# STM32H5E4xx register map
File version: 1.0
Registers are 32-bit, read-write, reset 0x0 unless marked. A register's access mark holds for its fields unless they carry their own. Offsets are from the block's base; [hi:lo] are bit positions; 'fields as' and 'values as' point back to an identical list.

## RSSLIB_PFUNC — RSSLib function pointer structure
Base 0x0BFB6068
0x00 DataProvisioning ro
0x10 JumpHDPLvl2 ro
0x14 JumpHDPLvl3 ro
0x18 JumpHDPLvl3NS ro

## NSSLIB_PFUNC — RSSLib secure callable function pointer structure
Base 0x0BFB606C
0x00 JumpHDPLvl2 ro
0x04 JumpHDPLvl3 ro

## WWDG
Base 0x40002C00
Same registers: WWDG_S 0x50002C00
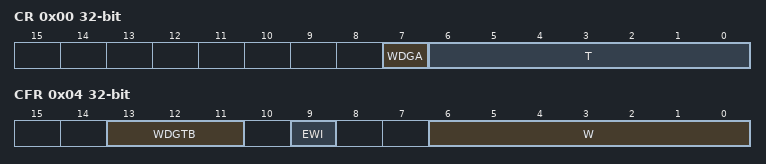
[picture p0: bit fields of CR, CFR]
0x00 CR — WWDG Control register
  [7] WDGA — Activation bit
  [6:0] T — T[6:0] bits (7-Bit counter (MSB to LSB))
0x04 CFR — WWDG Configuration register
  [13:11] WDGTB — WDGTB[2:0] bits (Timer Base)
    0=PRESCALER_1 (WWDG counter clock = (PCLK1/4096)/1); 1=PRESCALER_2 (WWDG counter clock = (PCLK1/4096)/2); 2=PRESCALER_4 (WWDG counter clock = (PCLK1/4096)/4); 3=PRESCALER_8 (WWDG counter clock = (PCLK1/4096)/8); 4=PRESCALER_16 (WWDG counter clock = (PCLK1/4096)/16); 5=PRESCALER_32 (WWDG counter clock = (PCLK1/4096)/32); 6=PRESCALER_64 (WWDG counter clock = (PCLK1/4096)/64); 7=PRESCALER_128 (WWDG counter clock = (PCLK1/4096)/128)
  [9] EWI — Early Wakeup Interrupt
  [6:0] W — W[6:0] bits (7-bit window value)
0x08 SR — WWDG Status register
  [0] EWIF — Early Wakeup Interrupt Flag

## IWDG
Base 0x40003000
Same registers: IWDG_S 0x50003000
0x00 KR — IWDG Key register
  [15:0] KEY — Key value (write only, read 0000h)
0x04 PR — IWDG Prescaler register
  [3:0] PR — PR[3:0] (Prescaler divider)
0x08 RLR — IWDG Reload register
  [11:0] RL — Watchdog counter reload value
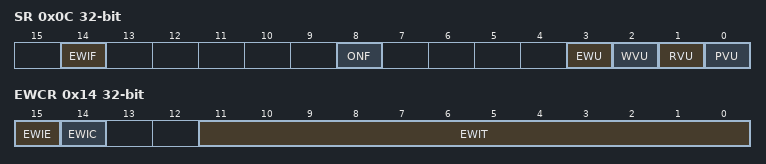
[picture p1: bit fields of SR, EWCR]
0x0C SR — IWDG Status register
  [14] EWIF — Watchdog early interrupt flag
  [8] ONF — Watchdog Enable status bit
  [3] EWU — Watchdog interrupt comparator value update
  [2] WVU — Watchdog counter window value update
  [1] RVU — Watchdog counter reload value update
  [0] PVU — Watchdog prescaler value update
0x10 WINR — IWDG Window register
  [11:0] WIN — Watchdog counter window value
0x14 EWCR — IWDG Early Wakeup register
  [15] EWIE — Watchdog early wakeup comparator value
  [14] EWIC — Watchdog early wakeup comparator value
  [11:0] EWIT — Watchdog early wakeup comparator value

## OPAMP1 — Operational Amplifier (OPAMP)
Base 0x40003400
Same registers: OPAMP1_S 0x50003400
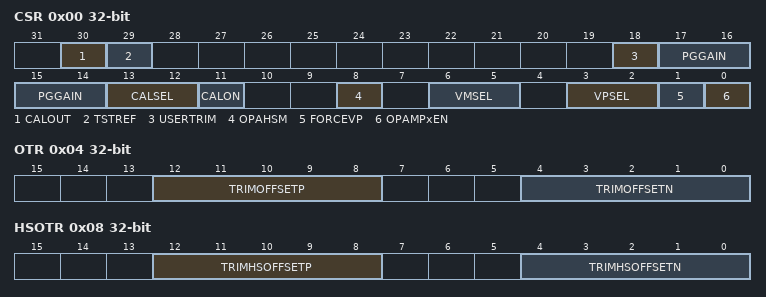
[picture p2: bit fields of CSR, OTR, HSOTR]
0x00 CSR — OPAMP control/status register
  [30] CALOUT — Calibration output
  [29] TSTREF — calibration reference voltage output
  [18] USERTRIM — User trimming enable
    0=FACTORY (OPAMP trimming factors set to factory values); 1=USER (OPAMP trimming factors set to user values)
  [17:14] PGGAIN — Programmable amplifier gain value
  [13:12] CALSEL — Calibration selection
  [11] CALON — Calibration mode enable
    0=FUNCTIONAL (OPAMP functional mode); 1=CALIBRATION (OPAMP calibration mode)
  [8] OPAHSM — high speed mode
  [6:5] VMSEL — Inverting input selection
    0=IO0; 1=IO1; 2=CONNECT_NO
  [3:2] VPSEL — Non inverted input selection
    0=IO0; 2=IO1; 1=DAC
  [1] FORCEVP — Force internal reference on VP
  [0] OPAMPxEN — OPAMP enable
0x04 OTR — OPAMP
  [12:8] TRIMOFFSETP — Trim for PMOS differential pairs
  [4:0] TRIMOFFSETN — Trim for NMOS differential pairs
0x08 HSOTR — OPAMP
  [12:8] TRIMHSOFFSETP — Trim for PMOS pairs
  [4:0] TRIMHSOFFSETN — Trim for NMOS pairs

## COMP12 — Comparator
Base 0x40004000
Same registers: COMP12_S 0x50004000
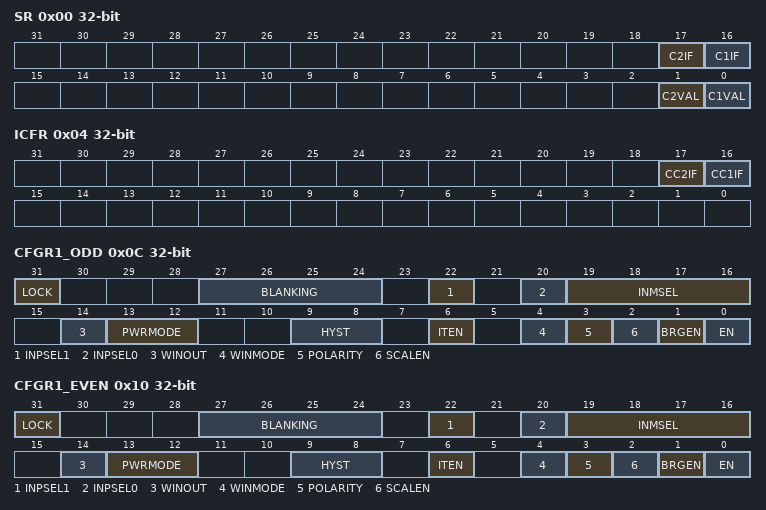
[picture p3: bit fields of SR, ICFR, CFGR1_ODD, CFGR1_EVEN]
0x00 SR — Comparator status register
  [17] C2IF, [16] C1IF, [1] C2VAL, [0] C1VAL
0x04 ICFR — Comparator interrupt clear flag register
  [17] CC2IF, [16] CC1IF
0x0C CFGR1_ODD — COMP control and status register located in register of comparator instance odd, used for bits common to several COMP instances
  [31] LOCK — COMP1 Lock Bit
  [27:24] BLANKING — COMP1 blanking source selection bits
    0=NONE (Comparator output without blanking); 1=TIM1_OC5 (Comparator output blanking source TIM1 OC5); 2=TIM2_OC3 (Comparator output blanking source TIM2 OC3); 3=TIM3_OC3; 4=TIM3_OC4 (Comparator output blanking source TIM3 OC4); 5=LPTIM1_OC2; 6=LPTIM2_OC2
  [22] INPSEL1 — COMP1 input plus 1 selection bit
  [20] INPSEL0 — COMP1 input plus 0 selection bit
  [19:16] INMSEL — COMP1 input minus selection bit
  [14] WINOUT — COMP1 window output selection bit
  [13:12] PWRMODE — COMP1 Power Mode of the comparator
    0=HIGHSPEED (COMP power mode to high speed); 1=MEDIUMSPEED (COMP power mode to medium speed); 3=ULTRALOWPOWER
  [9:8] HYST — COMP1 hysteresis selection bits
    0=NONE (No hysteresis); 1=LOW (Hysteresis level low); 2=MEDIUM (Hysteresis level medium); 3=HIGH (Hysteresis level high)
  [6] ITEN — COMP1 interrupt enable
  [4] WINMODE — COMP1 window mode selection bit
  [3] POLARITY — COMP1 polarity selection bit
    0=NONINVERTED; 1=INVERTED
  [2] SCALEN — COMP1 Voltage scaler enable bit
  [1] BRGEN — COMP1 Scaler bridge enable
  [0] EN — COMP1 enable bit
0x10 CFGR1_EVEN — COMP control and status register located in register of comparator instance even, used for bits common to several COMP instances
  fields as CFGR1_ODD
